# LPC55S16 register map
Vendor: nxp.com; File version: 1.0
CPU: CM33 r2p0, little endian, MPU, FPU, VTOR, 3 interrupt priority bits
Registers are 32-bit, read-write, reset 0x0 unless marked. A register's access mark holds for its fields unless they carry their own. Offsets are from the block's base; [hi:lo] are bit positions; {n}, {i} and the like mark numbered series; 'fields as' and 'values as' point back to an identical list.

## AHB_SECURE_CTRL — AHB secure controller
Base 0x400AC000
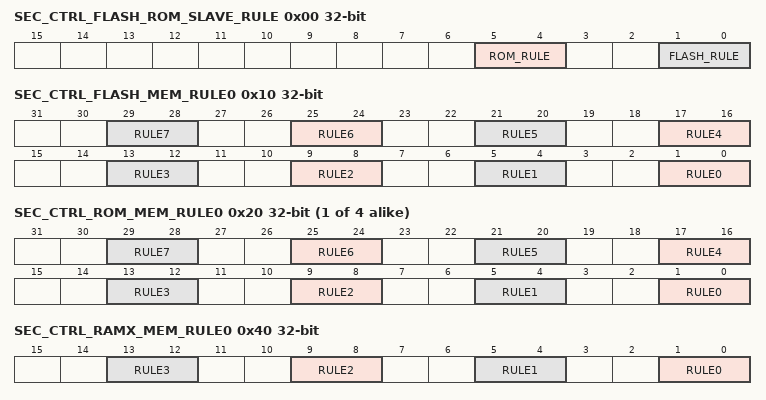
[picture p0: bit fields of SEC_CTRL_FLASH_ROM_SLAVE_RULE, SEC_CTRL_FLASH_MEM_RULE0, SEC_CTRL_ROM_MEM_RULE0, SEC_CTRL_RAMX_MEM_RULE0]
0x00 SEC_CTRL_FLASH_ROM_SLAVE_RULE — Security access rules for Flash and ROM slaves.
  [5:4] ROM_RULE — Security access rules for the whole ROM : 0x0300_0000 - 0x0301_FFFF
    0=ENUM_NS_NP (Non-secure and Non-priviledge user access allowed.); 1=ENUM_NS_P (Non-secure and Privilege access allowed.); 2=ENUM_S_NP (Secure and Non-priviledge user access allowed.); 3=ENUM_S_P (Secure and Priviledge user access allowed.)
  [1:0] FLASH_RULE — Security access rules for the whole FLASH : 0x0000_0000 - 0x0003_FFFF
    values as ROM_RULE
0x10 SEC_CTRL_FLASH_MEM_RULE0 — Security access rules for FLASH sector 0 to sector 7. Each Flash sector is 32 Kbytes. There are 8 FLASH sectors in total.
  [all] fields
    values as SEC_CTRL_FLASH_ROM_SLAVE_RULE.ROM_RULE
  [4n+1:4n] RULE{n} (n=0..7) — secure control rule{n}. it can be set when check_reg's write_lock is '0'
{0x20+4i} SEC_CTRL_ROM_MEM_RULE{i} (i=0..3) — Security access rules for ROM sector 0 to sector 31. Each ROM sector is 4 Kbytes. There are 32 ROM sectors in total.
  fields as SEC_CTRL_FLASH_MEM_RULE0
0x30 SEC_CTRL_RAMX_SLAVE_RULE — Security access rules for RAMX slaves.
  [1:0] RAMX_RULE — Security access rules for the whole RAMX : 0x0400_0000 - 0x0400_7FFF
    values as SEC_CTRL_FLASH_ROM_SLAVE_RULE.ROM_RULE
0x40 SEC_CTRL_RAMX_MEM_RULE0 — Security access rules for RAMX slaves.
  [all] fields
    values as SEC_CTRL_FLASH_ROM_SLAVE_RULE.ROM_RULE
  [4n+1:4n] RULE{n} (n=0..3) — secure control rule{n}. it can be set when check_reg's write_lock is '0'
0x50 SEC_CTRL_RAM0_SLAVE_RULE — Security access rules for RAM0 slaves.
  [1:0] RAM0_RULE — Security access rules for the whole RAM0 : 0x2000_0000 - 0x2000_7FFF
    values as SEC_CTRL_FLASH_ROM_SLAVE_RULE.ROM_RULE
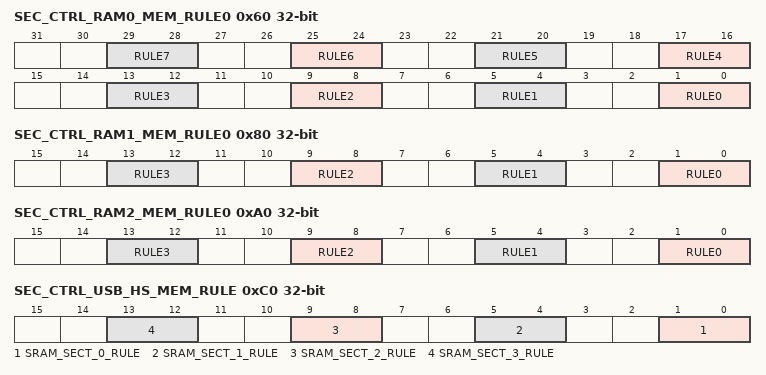
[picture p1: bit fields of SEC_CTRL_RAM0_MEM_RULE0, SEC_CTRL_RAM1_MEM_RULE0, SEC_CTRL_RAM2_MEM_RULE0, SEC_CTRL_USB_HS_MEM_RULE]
0x60 SEC_CTRL_RAM0_MEM_RULE0 — Security access rules for RAM0 slaves.
  fields as SEC_CTRL_FLASH_MEM_RULE0
0x70 SEC_CTRL_RAM1_SLAVE_RULE — Security access rules for RAM1 slaves.
  [1:0] RAM1_RULE — Security access rules for the whole RAM1 : 0x2000_8000 - 0x2000_BFFF
    values as SEC_CTRL_FLASH_ROM_SLAVE_RULE.ROM_RULE
0x80 SEC_CTRL_RAM1_MEM_RULE0 — Security access rules for RAM1 slaves.
  fields as SEC_CTRL_RAMX_MEM_RULE0
0x90 SEC_CTRL_RAM2_SLAVE_RULE — Security access rules for RAM2 slaves.
  [1:0] RAM2_RULE — Security access rules for the whole RAM2 : 0x2000_C000 - 0x2000_FFFF
    values as SEC_CTRL_FLASH_ROM_SLAVE_RULE.ROM_RULE
0xA0 SEC_CTRL_RAM2_MEM_RULE0 — Security access rules for RAM2 slaves.
  fields as SEC_CTRL_RAMX_MEM_RULE0
0xB0 SEC_CTRL_USB_HS_SLAVE_RULE — Security access rules for USB High speed RAM slaves.
  [1:0] RAM_USB_HS_RULE — Security access rules for the whole USB High Speed RAM : 0x2001_0000 - 0x2001_3FFF
    values as SEC_CTRL_FLASH_ROM_SLAVE_RULE.ROM_RULE
0xC0 SEC_CTRL_USB_HS_MEM_RULE — Security access rules for RAM_USB_HS.
  [all] fields
    values as SEC_CTRL_FLASH_ROM_SLAVE_RULE.ROM_RULE
  [4n+1:4n] SRAM_SECT_{n}_RULE (n=0..3) — Address space: 0x2001_{1000n:04} - 0x2001_{n}FFF
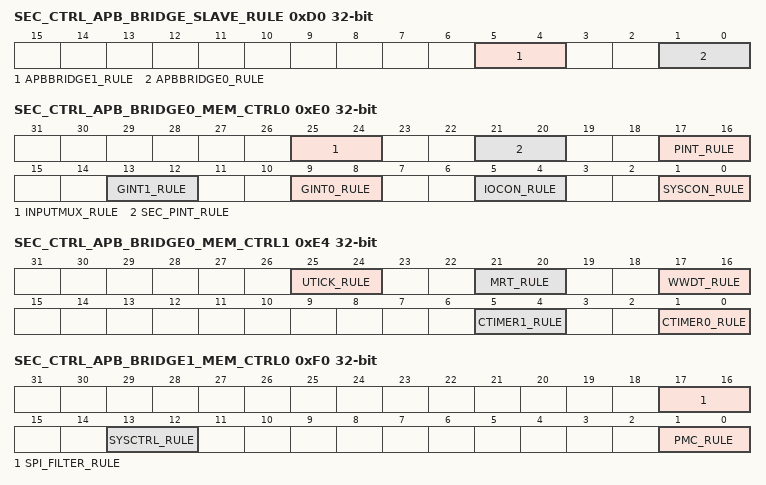
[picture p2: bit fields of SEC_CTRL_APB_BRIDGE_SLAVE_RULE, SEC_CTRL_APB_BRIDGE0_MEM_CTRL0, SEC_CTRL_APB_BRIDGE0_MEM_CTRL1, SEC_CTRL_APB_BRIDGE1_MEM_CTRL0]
0xD0 SEC_CTRL_APB_BRIDGE_SLAVE_RULE — Security access rules for both APB Bridges slaves.
  [5:4] APBBRIDGE1_RULE — Security access rules for the whole APB Bridge 1
    values as SEC_CTRL_FLASH_ROM_SLAVE_RULE.ROM_RULE
  [1:0] APBBRIDGE0_RULE — Security access rules for the whole APB Bridge 0
    values as SEC_CTRL_FLASH_ROM_SLAVE_RULE.ROM_RULE
0xE0 SEC_CTRL_APB_BRIDGE0_MEM_CTRL0 — Security access rules for APB Bridge 0 peripherals. Each APB bridge sector is 4 Kbytes. There are 32 APB Bridge 0 sectors in total.
  [all] fields
    values as SEC_CTRL_FLASH_ROM_SLAVE_RULE.ROM_RULE
  [25:24] INPUTMUX_RULE — Peripheral input multiplexing
  [21:20] SEC_PINT_RULE — Secure Pin Interrupt and Pattern match
  [17:16] PINT_RULE — Pin Interrupt and Pattern match
  [13:12] GINT1_RULE — GPIO input Interrupt 1
  [9:8] GINT0_RULE — GPIO input Interrupt 0
  [5:4] IOCON_RULE — I/O Configuration
  [1:0] SYSCON_RULE — System Configuration
0xE4 SEC_CTRL_APB_BRIDGE0_MEM_CTRL1 — Security access rules for APB Bridge 0 peripherals. Each APB bridge sector is 4 Kbytes. There are 32 APB Bridge 0 sectors in total.
  [all] fields
    values as SEC_CTRL_FLASH_ROM_SLAVE_RULE.ROM_RULE
  [25:24] UTICK_RULE — Micro-Timer
  [21:20] MRT_RULE — Multi-rate Timer
  [17:16] WWDT_RULE — Windiwed wtachdog Timer
  [5:4] CTIMER1_RULE — Standard counter/Timer 1
  [1:0] CTIMER0_RULE — Standard counter/Timer 0
0xE8 SEC_CTRL_APB_BRIDGE0_MEM_CTRL2 — Security access rules for APB Bridge 0 peripherals. Each APB bridge sector is 4 Kbytes. There are 32 APB Bridge 0 sectors in total.
  [13:12] ANACTRL_RULE — Analog Modules controller
    values as SEC_CTRL_FLASH_ROM_SLAVE_RULE.ROM_RULE
0xF0 SEC_CTRL_APB_BRIDGE1_MEM_CTRL0 — Security access rules for APB Bridge 1 peripherals. Each APB bridge sector is 4 Kbytes. There are 32 APB Bridge 1 sectors in total.
  [all] fields
    values as SEC_CTRL_FLASH_ROM_SLAVE_RULE.ROM_RULE
  [17:16] SPI_FILTER_RULE — SPI FILTER control
  [13:12] SYSCTRL_RULE — System Controller
  [1:0] PMC_RULE — Power Management Controller
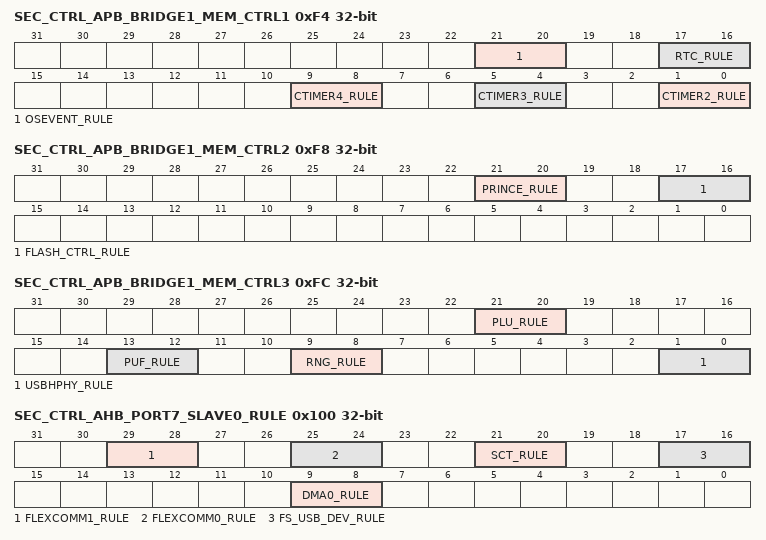
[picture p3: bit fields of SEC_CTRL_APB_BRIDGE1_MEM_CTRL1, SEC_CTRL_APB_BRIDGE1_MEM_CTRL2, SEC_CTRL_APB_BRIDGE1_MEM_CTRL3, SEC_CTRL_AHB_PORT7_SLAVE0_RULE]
0xF4 SEC_CTRL_APB_BRIDGE1_MEM_CTRL1 — Security access rules for APB Bridge 1 peripherals. Each APB bridge sector is 4 Kbytes. There are 32 APB Bridge 1 sectors in total.
  [all] fields
    values as SEC_CTRL_FLASH_ROM_SLAVE_RULE.ROM_RULE
  [21:20] OSEVENT_RULE — OS Event Timer
  [17:16] RTC_RULE — Real Time Counter
  [9:8] CTIMER4_RULE — Standard counter/Timer 4
  [5:4] CTIMER3_RULE — Standard counter/Timer 3
  [1:0] CTIMER2_RULE — Standard counter/Timer 2
0xF8 SEC_CTRL_APB_BRIDGE1_MEM_CTRL2 — Security access rules for APB Bridge 1 peripherals. Each APB bridge sector is 4 Kbytes. There are 32 APB Bridge 1 sectors in total.
  [21:20] PRINCE_RULE — Prince
    values as SEC_CTRL_FLASH_ROM_SLAVE_RULE.ROM_RULE
  [17:16] FLASH_CTRL_RULE — Flash Controller
    values as SEC_CTRL_FLASH_ROM_SLAVE_RULE.ROM_RULE
0xFC SEC_CTRL_APB_BRIDGE1_MEM_CTRL3 — Security access rules for APB Bridge 1 peripherals. Each APB bridge sector is 4 Kbytes. There are 32 APB Bridge 1 sectors in total.
  [all] fields
    values as SEC_CTRL_FLASH_ROM_SLAVE_RULE.ROM_RULE
  [21:20] PLU_RULE — Programmable Look-Up logic
  [13:12] PUF_RULE — PUF
  [9:8] RNG_RULE — True Random Number Generator
  [1:0] USBHPHY_RULE — USB High Speed Phy controller
0x100 SEC_CTRL_AHB_PORT7_SLAVE0_RULE — Security access rules for AHB peripherals.
  [all] fields
    values as SEC_CTRL_FLASH_ROM_SLAVE_RULE.ROM_RULE
  [29:28] FLEXCOMM1_RULE — Flexcomm interface 1
  [25:24] FLEXCOMM0_RULE — Flexcomm interface 0
  [21:20] SCT_RULE — SCTimer
  [17:16] FS_USB_DEV_RULE — USB Full-speed device
  [9:8] DMA0_RULE — DMA Controller
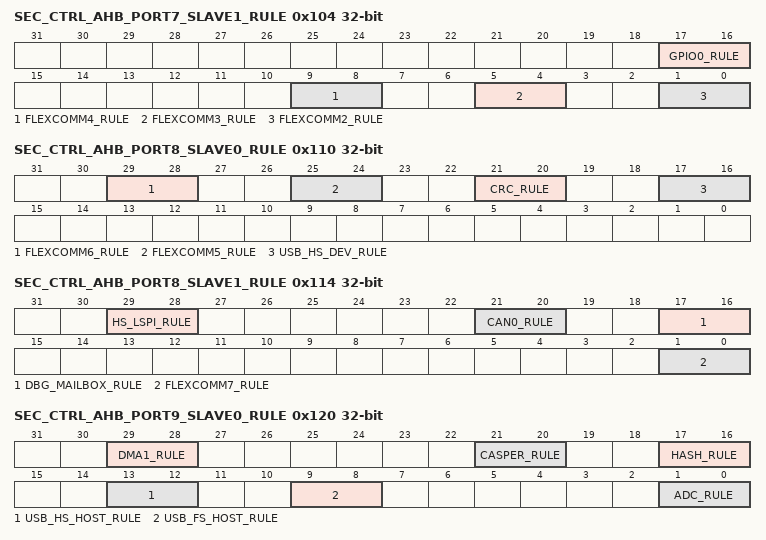
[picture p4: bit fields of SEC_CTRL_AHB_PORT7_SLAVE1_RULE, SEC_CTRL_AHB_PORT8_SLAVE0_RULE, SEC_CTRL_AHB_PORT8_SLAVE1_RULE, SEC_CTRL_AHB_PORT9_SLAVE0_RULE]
0x104 SEC_CTRL_AHB_PORT7_SLAVE1_RULE — Security access rules for AHB peripherals.
  [all] fields
    values as SEC_CTRL_FLASH_ROM_SLAVE_RULE.ROM_RULE
  [17:16] GPIO0_RULE — High Speed GPIO
  [9:8] FLEXCOMM4_RULE — Flexcomm interface 4
  [5:4] FLEXCOMM3_RULE — Flexcomm interface 3
  [1:0] FLEXCOMM2_RULE — Flexcomm interface 2
0x110 SEC_CTRL_AHB_PORT8_SLAVE0_RULE — Security access rules for AHB peripherals.
  [all] fields
    values as SEC_CTRL_FLASH_ROM_SLAVE_RULE.ROM_RULE
  [29:28] FLEXCOMM6_RULE — Flexcomm interface 6
  [25:24] FLEXCOMM5_RULE — Flexcomm interface 5
  [21:20] CRC_RULE — CRC engine
  [17:16] USB_HS_DEV_RULE — USB high Speed device registers
0x114 SEC_CTRL_AHB_PORT8_SLAVE1_RULE — Security access rules for AHB peripherals.
  [all] fields
    values as SEC_CTRL_FLASH_ROM_SLAVE_RULE.ROM_RULE
  [29:28] HS_LSPI_RULE — High Speed SPI
  [21:20] CAN0_RULE — CAN-FD
  [17:16] DBG_MAILBOX_RULE — Debug mailbox (aka ISP-AP)
  [1:0] FLEXCOMM7_RULE — Flexcomm interface 7
0x120 SEC_CTRL_AHB_PORT9_SLAVE0_RULE — Security access rules for AHB peripherals.
  [all] fields
    values as SEC_CTRL_FLASH_ROM_SLAVE_RULE.ROM_RULE
  [29:28] DMA1_RULE — DMA Controller (Secure)
  [21:20] CASPER_RULE — RSA/ECC crypto accelerator
  [17:16] HASH_RULE — SHA-2 crypto registers
  [13:12] USB_HS_HOST_RULE — USB High speed host registers
  [9:8] USB_FS_HOST_RULE — USB Full Speed Host registers.
  [1:0] ADC_RULE — ADC
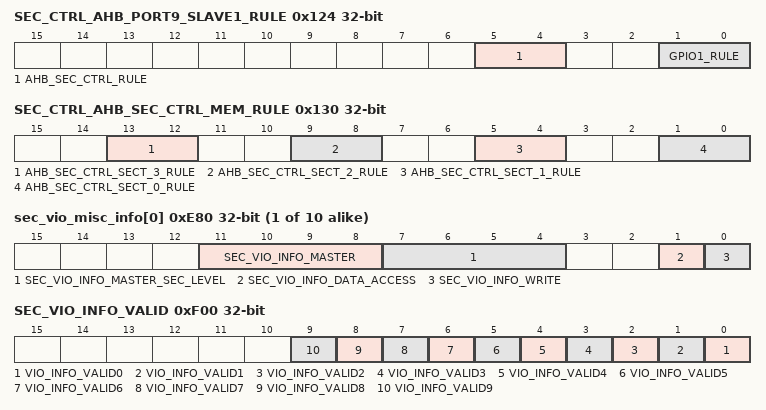
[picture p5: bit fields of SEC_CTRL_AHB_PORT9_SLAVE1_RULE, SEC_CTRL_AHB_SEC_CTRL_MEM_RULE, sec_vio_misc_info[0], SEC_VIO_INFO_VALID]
0x124 SEC_CTRL_AHB_PORT9_SLAVE1_RULE — Security access rules for AHB peripherals.
  [5:4] AHB_SEC_CTRL_RULE — AHB Secure Controller
    values as SEC_CTRL_FLASH_ROM_SLAVE_RULE.ROM_RULE
  [1:0] GPIO1_RULE — Secure High Speed GPIO
    values as SEC_CTRL_FLASH_ROM_SLAVE_RULE.ROM_RULE
0x130 SEC_CTRL_AHB_SEC_CTRL_MEM_RULE — Security access rules for AHB_SEC_CTRL_AHB.
  [all] fields
    values as SEC_CTRL_FLASH_ROM_SLAVE_RULE.ROM_RULE
  [13:12] AHB_SEC_CTRL_SECT_3_RULE — Address space: 0x400A_F000 - 0x400A_FFFF
  [9:8] AHB_SEC_CTRL_SECT_2_RULE — Address space: 0x400A_E000 - 0x400A_EFFF
  [5:4] AHB_SEC_CTRL_SECT_1_RULE — Address space: 0x400A_D000 - 0x400A_DFFF
  [1:0] AHB_SEC_CTRL_SECT_0_RULE — Address space: 0x400A_0000 - 0x400A_CFFF
{0xE00+4i} sec_vio_addr[{i}] (i=0..9) ro — most recent security violation address for AHB layer n
  [31:0] SEC_VIO_ADDR — security violation address for AHB layer
{0xE80+4i} sec_vio_misc_info[{i}] (i=0..9) ro — most recent security violation miscellaneous information for AHB layer n
  [11:8] SEC_VIO_INFO_MASTER — security violation master number
    0=CPU0 Code; 1=CPU0 System; 4=USB-HS Device; 5=SDMA0; 10=HASH; 11=USB-FS Host; 12=SDMA1; 13=CAN-FD
  [7:4] SEC_VIO_INFO_MASTER_SEC_LEVEL — bit [5:4]: master sec level and privilege level bit [7:6]: anti-pol value for master sec level and privilege level
  [1] SEC_VIO_INFO_DATA_ACCESS — security violation access data/code indicator.
    0=CODE (Code access.); 1=DATA (Data access.)
  [0] SEC_VIO_INFO_WRITE — security violation access read/write indicator.
    0=READ (Read access.); 1=WRITE (Write access.)
0xF00 SEC_VIO_INFO_VALID — security violation address/information registers valid flags
  [all] fields
    0=NOT_VALID; 1=VALID (Valid (violation occurred).)
  [n] VIO_INFO_VALID{n} (n=0..9) — violation information valid flag for AHB port {n}. Write 1 to clear.
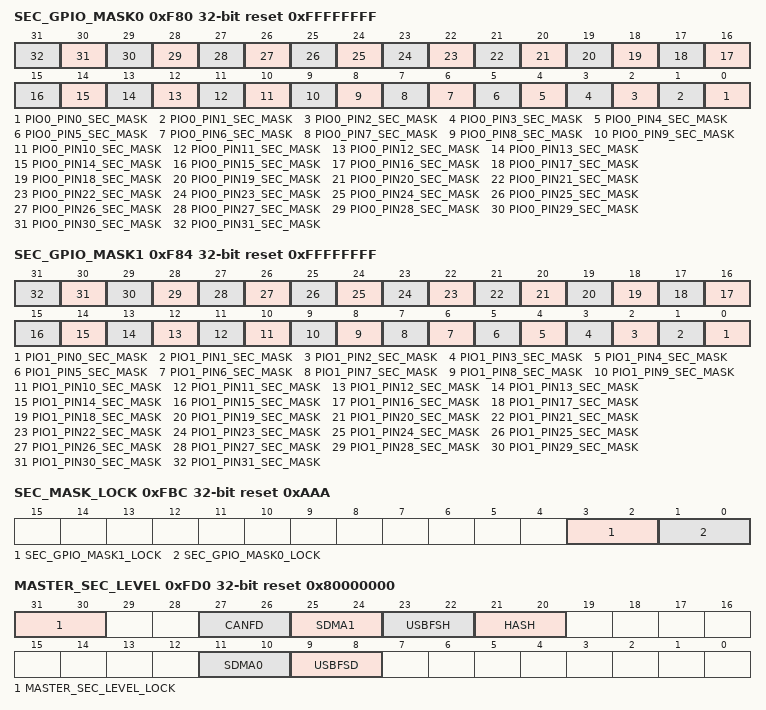
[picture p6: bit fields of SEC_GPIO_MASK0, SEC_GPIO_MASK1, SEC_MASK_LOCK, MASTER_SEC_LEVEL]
0xF80 SEC_GPIO_MASK0 reset 0xFFFFFFFF — Secure GPIO mask for port 0 pins.
  [all] fields
    0=BLOCKED (Pin state is blocked to non-secure world.); 1=READABLE (Pin state is readable by non-secure world.)
  [n] PIO0_PIN{n}_SEC_MASK (n=0..31) — Secure mask for pin P0_{n}
0xF84 SEC_GPIO_MASK1 reset 0xFFFFFFFF — Secure GPIO mask for port 1 pins.
  [all] fields
    values as the fields of SEC_GPIO_MASK0
  [n] PIO1_PIN{n}_SEC_MASK (n=0..31) — Secure mask for pin P1_{n}
0xFBC SEC_MASK_LOCK reset 0xAAA — Security General Purpose register access control.
  [3:2] SEC_GPIO_MASK1_LOCK — SEC_GPIO_MASK1 register write-lock.
    1=BLOCKED (Restricted mode.); 2=WRITABLE
  [1:0] SEC_GPIO_MASK0_LOCK — SEC_GPIO_MASK0 register write-lock.
    1=BLOCKED (Restricted mode.); 2=WRITABLE
0xFD0 MASTER_SEC_LEVEL reset 0x80000000 — master secure level register
  [31:30] MASTER_SEC_LEVEL_LOCK — MASTER_SEC_LEVEL write-lock.
    1=BLOCKED (Restricted mode.); 2=WRITABLE
  [27:26] CANFD
    values as SEC_CTRL_FLASH_ROM_SLAVE_RULE.ROM_RULE
  [25:24] SDMA1 — System DMA 1 security level.
    values as SEC_CTRL_FLASH_ROM_SLAVE_RULE.ROM_RULE
  [23:22] USBFSH — USB Full speed Host.
    values as SEC_CTRL_FLASH_ROM_SLAVE_RULE.ROM_RULE
  [21:20] HASH
    values as SEC_CTRL_FLASH_ROM_SLAVE_RULE.ROM_RULE
  [11:10] SDMA0 — System DMA 0.
    values as SEC_CTRL_FLASH_ROM_SLAVE_RULE.ROM_RULE
  [9:8] USBFSD — USB Full Speed Device.
    values as SEC_CTRL_FLASH_ROM_SLAVE_RULE.ROM_RULE
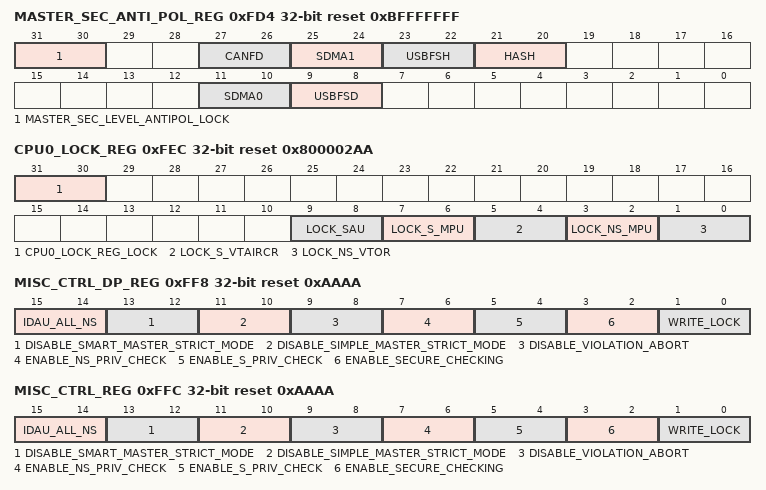
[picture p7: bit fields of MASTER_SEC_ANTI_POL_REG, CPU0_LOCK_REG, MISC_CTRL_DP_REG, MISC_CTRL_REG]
0xFD4 MASTER_SEC_ANTI_POL_REG reset 0xBFFFFFFF — master secure level anti-pole register
  [31:30] MASTER_SEC_LEVEL_ANTIPOL_LOCK — MASTER_SEC_ANTI_POL_REG register write-lock.
    1=BLOCKED (Restricted mode.); 2=WRITABLE
  [27:26] CANFD — CAN FD. Must be equal to NOT(MASTER_SEC_LEVEL.CANFD)
    0=ENUM_S_P (Secure and Priviledge user access allowed.); 1=ENUM_S_NP (Secure and Non-priviledge user access allowed.); 2=ENUM_NS_P (Non-secure and Privilege access allowed.); 3=ENUM_NS_NP (Non-secure and Non-priviledge user access allowed.)
  [25:24] SDMA1 — System DMA 1 security level. Must be equal to NOT(MASTER_SEC_LEVEL.SDMA1)
    values as CANFD
  [23:22] USBFSH — USB Full speed Host. Must be equal to NOT(MASTER_SEC_LEVEL.USBFSH)
    values as CANFD
  [21:20] HASH — Hash. Must be equal to NOT(MASTER_SEC_LEVEL.HASH)
    values as CANFD
  [11:10] SDMA0 — System DMA 0. Must be equal to NOT(MASTER_SEC_LEVEL.SDMA0)
    values as CANFD
  [9:8] USBFSD — USB Full Speed Device. Must be equal to NOT(MASTER_SEC_LEVEL.USBFSD)
    values as CANFD
0xFEC CPU0_LOCK_REG reset 0x800002AA — Miscalleneous control signals for in Cortex M33 (CPU0)
  [all] fields
    1=BLOCKED (Restricted mode.); 2=WRITABLE
  [31:30] CPU0_LOCK_REG_LOCK — CPU0_LOCK_REG write-lock.
  [9:8] LOCK_SAU — Cortex M33 (CPU0) SAU registers write-lock.
  [7:6] LOCK_S_MPU — Cortex M33 (CPU0) Secure MPU registers write-lock.
  [5:4] LOCK_S_VTAIRCR — Cortex M33 (CPU0) VTOR_S, AIRCR.PRIS, IRCR.BFHFNMINS registers write-lock.
  [3:2] LOCK_NS_MPU — Cortex M33 (CPU0) non-secure MPU register write-lock.
  [1:0] LOCK_NS_VTOR — Cortex M33 (CPU0) VTOR_NS register write-lock.
0xFF8 MISC_CTRL_DP_REG reset 0xAAAA — secure control duplicate register
  [15:14] IDAU_ALL_NS — Disable IDAU.
    1=DISABLE (IDAU is disable.); 2=ENABLE (IDAU is enabled.)
  [13:12] DISABLE_SMART_MASTER_STRICT_MODE
    1=TIER_MODE (Smart master in tier mode.); 2=STRICT_MODE (Smart master in strict mode.)
  [11:10] DISABLE_SIMPLE_MASTER_STRICT_MODE
    1=TIER_MODE (Simple master in tier mode.); 2=STRICT_MODE (Simple master in strict mode.)
  [9:8] DISABLE_VIOLATION_ABORT — Disable secure violation abort.
    1=DISABLE (Disable abort fort secure checker.); 2=ENABLE (Enable abort fort secure checker.)
  [7:6] ENABLE_NS_PRIV_CHECK — Enable non-secure privilege check for AHB matrix.
    1=ENABLE (Restricted mode.); 2=DISABLE (Disable check.)
  [5:4] ENABLE_S_PRIV_CHECK — Enable secure privilege check for AHB matrix.
    1=ENABLE (Restricted mode.); 2=DISABLE (Disable check.)
  [3:2] ENABLE_SECURE_CHECKING — Enable secure check for AHB matrix.
    1=ENABLE (Restricted mode.); 2=DISABLE (Disable check.)
  [1:0] WRITE_LOCK
    1=RESTRICTED (Restricted mode.); 2=ACCESSIBLE (Secure control registers can be written.)
0xFFC MISC_CTRL_REG reset 0xAAAA — secure control register
  [15:14] IDAU_ALL_NS — Disable IDAU.
    1=DISABLE (IDAU is disable.); 2=ENABLE (IDAU is enabled.)
  [13:12] DISABLE_SMART_MASTER_STRICT_MODE
    values as MISC_CTRL_DP_REG.DISABLE_SMART_MASTER_STRICT_MODE
  [11:10] DISABLE_SIMPLE_MASTER_STRICT_MODE
    values as MISC_CTRL_DP_REG.DISABLE_SIMPLE_MASTER_STRICT_MODE
  [9:8] DISABLE_VIOLATION_ABORT — Disable secure violation abort.
    values as MISC_CTRL_DP_REG.DISABLE_VIOLATION_ABORT
  [7:6] ENABLE_NS_PRIV_CHECK — Enable non-secure privilege check for AHB matrix.
    1=ENABLE (Enabled (restricted mode)); 2=DISABLE (Disable check.)
  [5:4] ENABLE_S_PRIV_CHECK — Enable secure privilege check for AHB matrix.
    values as ENABLE_NS_PRIV_CHECK
  [3:2] ENABLE_SECURE_CHECKING — Enable secure check for AHB matrix.
    values as ENABLE_NS_PRIV_CHECK
  [1:0] WRITE_LOCK
    values as MISC_CTRL_DP_REG.WRITE_LOCK
